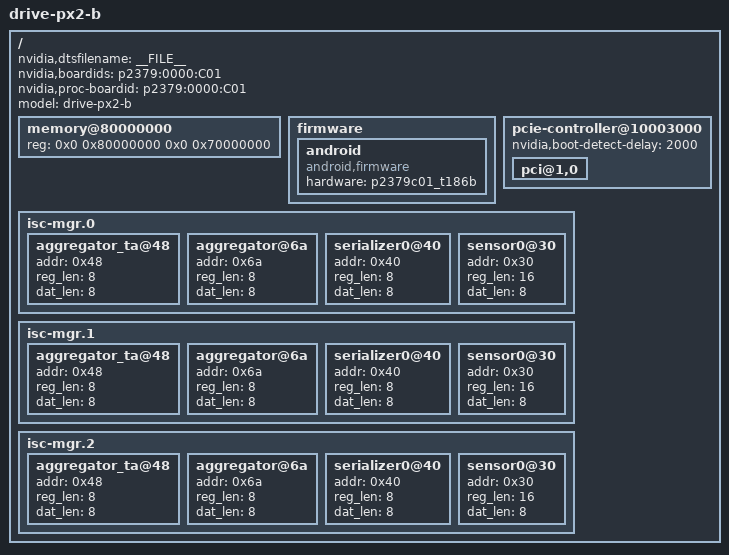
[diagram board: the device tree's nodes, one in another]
/*
 * tegra186-priv-vcm31-p2379-safety-0000-c01-00-base-b.dts: P2379-C01 TB base dts
 * file
 *
 * Copyright (c) 2016, NVIDIA CORPORATION.  All rights reserved.
 *
 * This program is free software; you can redistribute it and/or modify
 * it under the terms of the GNU General Public License as published by
 * the Free Software Foundation; version 2 of the License.
 *
 * This program is distributed in the hope that it will be useful, but WITHOUT
 * ANY WARRANTY; without even the implied warranty of MERCHANTABILITY or
 * FITNESS FOR A PARTICULAR PURPOSE.  See the GNU General Public License for
 * more details.
 */

#include "tegra186-platforms/tegra186-vcm31-p2379-common.dtsi"
#include "tegra186-platforms/tegra186-vcm31-power-tree-p2379-0000-c01-00.dtsi"
#include "tegra186-platforms/tegra186-vcm31-62379-disp.dtsi"
#include "tegra186-platforms/tegra186-vcm31-camera-ape.dtsi"

/ {
	nvidia,dtsfilename = __FILE__;
	nvidia,boardids = "p2379:0000:C01";
	nvidia,proc-boardid = "p2379:0000:C01";
	model = "drive-px2-b";

	memory@80000000 {
		device_type = "memory";
		reg = <0x0 0x80000000 0x0 0x70000000>;
	};

	firmware {
		android {
			compatible = "android,firmware";
			hardware = "p2379c01_t186b";
		};
	};

	pcie-controller@10003000 {
		nvidia,boot-detect-delay = <2000>;
                pci@1,0 {
                        status = "okay";
                };
        };

	isc-mgr.0 {
		/* This node is to control the aggregator connected to Tegra A on Tegra B */
		aggregator_ta@48 {
			addr = <0x48>;  /* 7 bit slave address */
			reg_len = <8>;  /* 8 bit register length */
			dat_len = <8>;  /* 8 bit data length */
		};
		aggregator@6a {
			addr = <0x6a>;  /* 7 bit slave address */
			reg_len = <8>;  /* 8 bit register length */
			dat_len = <8>;  /* 8 bit data length */
		};
		serializer0@40 {
			addr = <0x40>;  /* 7 bit slave address */
			reg_len = <8>;  /* 8 bit register length */
			dat_len = <8>;  /* 8 bit data length */
		};
		sensor0@30 {
			addr = <0x30>;  /* 7 bit slave address */
			reg_len = <16>; /* 16 bit register length */
			dat_len = <8>;  /* 8 bit data length */
		};
	};

	isc-mgr.1 {
		/* This node is to control the aggregator connected to Tegra A on Tegra B */
		aggregator_ta@48 {
			addr = <0x48>;  /* 7 bit slave address */
			reg_len = <8>;  /* 8 bit register length */
			dat_len = <8>;  /* 8 bit data length */
		};
		aggregator@6a {
			addr = <0x6a>;  /* 7 bit slave address */
			reg_len = <8>;  /* 8 bit register length */
			dat_len = <8>;  /* 8 bit data length */
		};
		serializer0@40 {
			addr = <0x40>;  /* 7 bit slave address */
			reg_len = <8>;  /* 8 bit register length */
			dat_len = <8>;  /* 8 bit data length */
		};
		sensor0@30 {
			addr = <0x30>;  /* 7 bit slave address */
			reg_len = <16>; /* 16 bit register length */
			dat_len = <8>;  /* 8 bit data length */
		};
	};

	isc-mgr.2 {
		/* This node is to control the aggregator connected to Tegra A on Tegra B */
		aggregator_ta@48 {
			addr = <0x48>;  /* 7 bit slave address */
			reg_len = <8>;  /* 8 bit register length */
			dat_len = <8>;  /* 8 bit data length */
		};
		aggregator@6a {
			addr = <0x6a>;  /* 7 bit slave address */
			reg_len = <8>;  /* 8 bit register length */
			dat_len = <8>;  /* 8 bit data length */
		};
		serializer0@40 {
			addr = <0x40>;  /* 7 bit slave address */
			reg_len = <8>;  /* 8 bit register length */
			dat_len = <8>;  /* 8 bit data length */
		};
		sensor0@30 {
			addr = <0x30>;  /* 7 bit slave address */
			reg_len = <16>; /* 16 bit register length */
			dat_len = <8>;  /* 8 bit data length */
		};
	};
};
